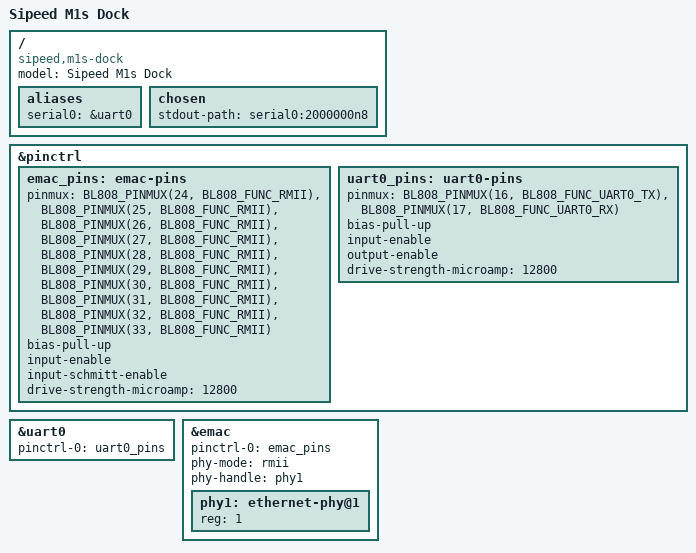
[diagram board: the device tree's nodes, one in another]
// SPDX-License-Identifier: (GPL-2.0+ or MIT)
/*
 * Copyright (C) 2022 Jisheng Zhang <jszhang@kernel.org>
 */

/dts-v1/;

#include "bl808-sipeed-m1s.dtsi"

/ {
	model = "Sipeed M1s Dock";
	compatible = "sipeed,m1s-dock", "sipeed,m1s", "bouffalolab,bl808";

	aliases {
		serial0 = &uart0;
	};

	chosen {
		stdout-path = "serial0:2000000n8";
	};
};

&pinctrl {
	emac_pins: emac-pins {
		pinmux = <BL808_PINMUX(24, BL808_FUNC_RMII)>,
			 <BL808_PINMUX(25, BL808_FUNC_RMII)>,
			 <BL808_PINMUX(26, BL808_FUNC_RMII)>,
			 <BL808_PINMUX(27, BL808_FUNC_RMII)>,
			 <BL808_PINMUX(28, BL808_FUNC_RMII)>,
			 <BL808_PINMUX(29, BL808_FUNC_RMII)>,
			 <BL808_PINMUX(30, BL808_FUNC_RMII)>,
			 <BL808_PINMUX(31, BL808_FUNC_RMII)>,
			 <BL808_PINMUX(32, BL808_FUNC_RMII)>,
			 <BL808_PINMUX(33, BL808_FUNC_RMII)>;
		bias-pull-up;
		input-enable;
		input-schmitt-enable;
		drive-strength-microamp = <12800>;
	};

	uart0_pins: uart0-pins {
		pinmux = <BL808_PINMUX(16, BL808_FUNC_UART0_TX)>,
			 <BL808_PINMUX(17, BL808_FUNC_UART0_RX)>;
		bias-pull-up;
		input-enable;
		output-enable;
		drive-strength-microamp = <12800>;
	};
};

&uart0 {
	pinctrl-0 = <&uart0_pins>;
	pinctrl-names = "default";
	status = "okay";
};

&emac {
	pinctrl-0 = <&emac_pins>;
	pinctrl-names = "default";
        phy-mode = "rmii";
        phy-handle = <&phy1>;
	status = "okay";

        phy1: ethernet-phy@1 {
                reg = <1>;
        };
};
